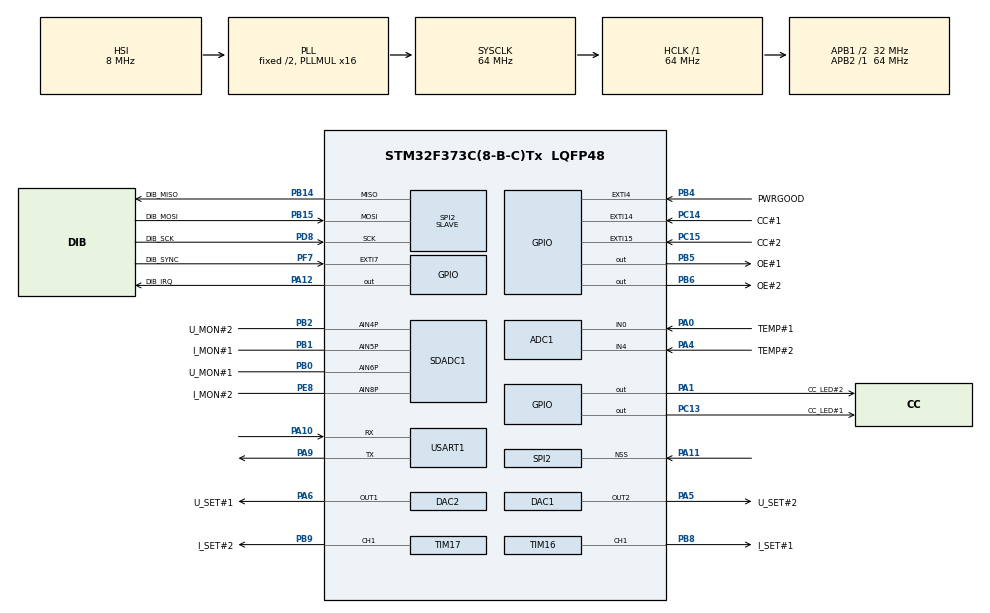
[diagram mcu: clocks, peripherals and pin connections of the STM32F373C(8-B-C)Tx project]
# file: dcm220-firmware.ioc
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ADC1.Channel-0\#ChannelRegularConversion=ADC_CHANNEL_0
ADC1.Channel-1\#ChannelRegularConversion=ADC_CHANNEL_4
ADC1.Channel-2\#ChannelRegularConversion=ADC_CHANNEL_TEMPSENSOR
ADC1.ContinuousConvMode=DISABLE
ADC1.DiscontinuousConvMode=DISABLE
ADC1.NbrOfConversion=3
ADC1.NbrOfConversionFlag=1
ADC1.Rank-0\#ChannelRegularConversion=1
ADC1.Rank-1\#ChannelRegularConversion=2
ADC1.Rank-2\#ChannelRegularConversion=3
ADC1.SamplingTime-0\#ChannelRegularConversion=ADC_SAMPLETIME_239CYCLES_5
ADC1.SamplingTime-1\#ChannelRegularConversion=ADC_SAMPLETIME_239CYCLES_5
ADC1.SamplingTime-2\#ChannelRegularConversion=ADC_SAMPLETIME_239CYCLES_5
ADC1.master=1
Dma.ADC1.0.Direction=DMA_PERIPH_TO_MEMORY
Dma.ADC1.0.Instance=DMA1_Channel1
Dma.ADC1.0.MemDataAlignment=DMA_MDATAALIGN_WORD
Dma.ADC1.0.MemInc=DMA_MINC_ENABLE
Dma.ADC1.0.Mode=DMA_NORMAL
Dma.ADC1.0.PeriphDataAlignment=DMA_PDATAALIGN_WORD
Dma.ADC1.0.PeriphInc=DMA_PINC_DISABLE
Dma.ADC1.0.Priority=DMA_PRIORITY_LOW
Dma.Request0=ADC1
Dma.Request1=SPI2_RX
Dma.Request2=SPI2_TX
Dma.SPI2_RX.1.Direction=DMA_PERIPH_TO_MEMORY
Dma.SPI2_RX.1.Instance=DMA1_Channel4
Dma.SPI2_RX.1.MemDataAlignment=DMA_MDATAALIGN_BYTE
Dma.SPI2_RX.1.MemInc=DMA_MINC_ENABLE
Dma.SPI2_RX.1.Mode=DMA_NORMAL
Dma.SPI2_RX.1.PeriphDataAlignment=DMA_PDATAALIGN_BYTE
Dma.SPI2_RX.1.PeriphInc=DMA_PINC_DISABLE
Dma.SPI2_RX.1.Priority=DMA_PRIORITY_LOW
Dma.SPI2_TX.2.Direction=DMA_MEMORY_TO_PERIPH
Dma.SPI2_TX.2.Instance=DMA1_Channel5
Dma.SPI2_TX.2.MemDataAlignment=DMA_MDATAALIGN_BYTE
Dma.SPI2_TX.2.MemInc=DMA_MINC_ENABLE
Dma.SPI2_TX.2.Mode=DMA_NORMAL
Dma.SPI2_TX.2.PeriphDataAlignment=DMA_PDATAALIGN_BYTE
Dma.SPI2_TX.2.PeriphInc=DMA_PINC_DISABLE
Dma.SPI2_TX.2.Priority=DMA_PRIORITY_LOW
Mcu.Family=STM32F3
Mcu.Name=STM32F373C(8-B-C)Tx
Mcu.Package=LQFP48
NVIC.ADC1_IRQn=true\:0\:0\:false\:false\:true\:true\:true
NVIC.DMA1_Channel1_IRQn=true\:0\:0\:false\:false\:true\:false\:true
NVIC.DMA1_Channel4_IRQn=true\:0\:0\:false\:false\:true\:false\:true
NVIC.DMA1_Channel5_IRQn=true\:0\:0\:false\:false\:true\:false\:true
NVIC.EXTI15_10_IRQn=true\:0\:0\:false\:false\:true\:true\:true
NVIC.EXTI4_IRQn=true\:0\:0\:false\:false\:true\:true\:true
NVIC.EXTI9_5_IRQn=true\:0\:0\:false\:false\:true\:true\:true
NVIC.PriorityGroup=NVIC_PRIORITYGROUP_4
PA0.GPIO_Label=TEMP\#1
PA0.Mode=IN0
PA0.Signal=ADC1_IN0
PA1.GPIO_Label=CC_LED\#2
PA1.Signal=GPIO_Output
PA10.Mode=Asynchronous
PA10.Signal=USART1_RX
PA11.Mode=NSS_Signal_Hard_Input
PA11.Signal=SPI2_NSS
PA12.GPIO_Label=DIB_IRQ
PA12.PinState=GPIO_PIN_SET
PA12.Signal=GPIO_Output
PA13.Mode=Trace_Asynchronous_SW
PA13.Signal=SYS_JTMS-SWDIO
PA14.Mode=Trace_Asynchronous_SW
PA14.Signal=SYS_JTCK-SWCLK
PA4.GPIO_Label=TEMP\#2
PA4.Mode=IN4
PA4.Signal=ADC1_IN4
PA5.GPIO_Label=U_SET\#2
PA5.Signal=COMP_DAC12_group
PA6.GPIO_Label=U_SET\#1
PA6.Signal=COMP_DAC21_group
PA9.Mode=Asynchronous
PA9.Signal=USART1_TX
PB0.GPIO_Label=U_MON\#1
PB0.Mode=IN6-Single-Ended zero reference
PB0.Signal=SDADC1_AIN6P
PB1.GPIO_Label=I_MON\#1
PB1.Mode=IN5-Single-Ended zero reference
PB1.Signal=SDADC1_AIN5P
PB14.GPIO_Label=DIB_MISO
PB14.Mode=Full_Duplex_Slave
PB14.Signal=SPI2_MISO
PB15.GPIO_Label=DIB_MOSI
PB15.Mode=Full_Duplex_Slave
PB15.Signal=SPI2_MOSI
PB2.GPIO_Label=U_MON\#2
PB2.Mode=IN4-Single-Ended zero reference
PB2.Signal=SDADC1_AIN4P
PB3.Mode=Trace_Asynchronous_SW
PB3.Signal=SYS_JTDO-TRACESWO
PB4.GPIO_Label=PWRGOOD
PB4.GPIO_ModeDefaultEXTI=GPIO_MODE_IT_RISING_FALLING
PB4.GPIO_PuPd=GPIO_PULLUP
PB4.Signal=GPXTI4
PB5.GPIO_Label=OE\#1
PB5.Signal=GPIO_Output
PB6.GPIO_Label=OE\#2
PB6.Signal=GPIO_Output
PB8.GPIO_Label=I_SET\#1
PB8.Signal=S_TIM16_CH1
PB9.GPIO_Label=I_SET\#2
PB9.Signal=S_TIM17_CH1
PC13.GPIO_Label=CC_LED\#1
PC13.Signal=GPIO_Output
PC14-OSC32_IN.GPIO_Label=CC\#1
PC14-OSC32_IN.GPIO_ModeDefaultEXTI=GPIO_MODE_IT_RISING_FALLING
PC14-OSC32_IN.Signal=GPXTI14
PC15-OSC32_OUT.GPIO_Label=CC\#2
PC15-OSC32_OUT.GPIO_ModeDefaultEXTI=GPIO_MODE_IT_RISING_FALLING
PC15-OSC32_OUT.Signal=GPXTI15
PD8.GPIO_Label=DIB_SCK
PD8.Mode=Full_Duplex_Slave
PD8.Signal=SPI2_SCK
PE8.GPIO_Label=I_MON\#2
PE8.Mode=IN8-Single-Ended zero reference
PE8.Signal=SDADC1_AIN8P
PF7.GPIO_Label=DIB_SYNC
PF7.Signal=GPXTI7
ProjectManager.HeapSize=0x200
ProjectManager.StackSize=0x400
ProjectManager.TargetToolchain=STM32CubeIDE
RCC.AHBFreq_Value=64000000
RCC.APB1CLKDivider=RCC_HCLK_DIV2
RCC.APB1Freq_Value=32000000
RCC.APB1TimFreq_Value=64000000
RCC.APB2Freq_Value=64000000
RCC.APB2TimFreq_Value=64000000
RCC.CortexFreq_Value=64000000
RCC.HCLKFreq_Value=64000000
RCC.HSE_VALUE=16000000
RCC.HSI_VALUE=8000000
RCC.LSE_VALUE=32768
RCC.PLLMUL=RCC_PLL_MUL16
RCC.RCC_PLLsource_Clock_Source_FROM_HSE=RCC_HSE_PREDIV_DIV2
RCC.SDADCPresc=RCC_SDADCSYSCLK_DIV16
RCC.SYSCLKFreq_VALUE=64000000
RCC.SYSCLKSource=RCC_SYSCLKSOURCE_PLLCLK
RCC.USBFreq_Value=64000000
SDADC1.Gain0=SDADC_GAIN_1
SDADC1.Gain1=SDADC_GAIN_2
SDADC1.InputMode0=SDADC_INPUT_MODE_SE_ZERO_REFERENCE
SDADC1.InputMode1=SDADC_INPUT_MODE_SE_ZERO_REFERENCE
SDADC1.NbrOfConversionFlag=1
SDADC1.ReferenceVoltage=SDADC_VREF_EXT
SH.COMP_DAC12_group.0=DAC1_OUT2,Enable_DAC_OUT2
SH.COMP_DAC21_group.0=DAC2_OUT1,DAC_OUT1
SH.S_TIM16_CH1.0=TIM16_CH1,PWM Generation1 CH1
SH.S_TIM17_CH1.0=TIM17_CH1,PWM Generation1 CH1
SPI2.DataSize=SPI_DATASIZE_8BIT
SPI2.Direction=SPI_DIRECTION_2LINES
SPI2.Mode=SPI_MODE_SLAVE
SPI2.VirtualNSS=VM_NSSHARD
SPI2.VirtualType=VM_SLAVE
TIM16.Channel=TIM_CHANNEL_1
TIM16.Period=1439
TIM16.Prescaler=0
TIM17.Channel=TIM_CHANNEL_1
TIM17.Period=1439
USART1.VirtualMode-Asynchronous=VM_ASYNC
VP_ADC1_TempSens_Input.Mode=IN-TempSens
VP_CRC_VS_CRC.Mode=CRC_Activate
VP_SDADC1_CONF0.Mode=ConfigZero
VP_SDADC1_CONF1.Mode=ConfigUn
VP_TIM16_VS_ClockSourceINT.Mode=Enable_Timer
VP_TIM17_VS_ClockSourceINT.Mode=Enable_Timer
board=custom

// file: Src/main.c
/* USER CODE BEGIN Header */
/**
  ******************************************************************************
  * @file           : main.c
  * @brief          : Main program body
  ******************************************************************************
  * @attention
  *
  * <h2><center>&copy; Copyright (c) 2019 STMicroelectronics.
  * All rights reserved.</center></h2>
  *
  * This software component is licensed by ST under BSD 3-Clause license,
  * the "License"; You may not use this file except in compliance with the
  * License. You may obtain a copy of the License at:
  *                        opensource.org/licenses/BSD-3-Clause
  *
  ******************************************************************************
  */
/* USER CODE END Header */

#include "main.h"

ADC_HandleTypeDef hadc1;
DMA_HandleTypeDef hdma_adc1;

CRC_HandleTypeDef hcrc;

DAC_HandleTypeDef hdac1;
DAC_HandleTypeDef hdac2;

SDADC_HandleTypeDef hsdadc1;

SPI_HandleTypeDef hspi2;
DMA_HandleTypeDef hdma_spi2_rx;
DMA_HandleTypeDef hdma_spi2_tx;

TIM_HandleTypeDef htim16;
TIM_HandleTypeDef htim17;

UART_HandleTypeDef huart1;

void SystemClock_Config(void);
static void MX_GPIO_Init(void);
static void MX_DMA_Init(void);
static void MX_ADC1_Init(void);
static void MX_SDADC1_Init(void);
static void MX_SPI2_Init(void);
static void MX_DAC1_Init(void);
static void MX_DAC2_Init(void);
static void MX_TIM16_Init(void);
static void MX_TIM17_Init(void);
static void MX_CRC_Init(void);
static void MX_USART1_UART_Init(void);

/* USER CODE BEGIN 0 */
void setup();
void loop();
/* USER CODE END 0 */

int main(void)
{

  /* MCU Configuration--------------------------------------------------------*/

  /* Reset of all peripherals, Initializes the Flash interface and the Systick. */
  HAL_Init();

  /* Configure the system clock */
  SystemClock_Config();

  /* Initialize all configured peripherals */
  MX_GPIO_Init();
  MX_DMA_Init();
  MX_ADC1_Init();
  MX_SDADC1_Init();
  MX_SPI2_Init();
  MX_DAC1_Init();
  MX_DAC2_Init();
  MX_TIM16_Init();
  MX_TIM17_Init();
  MX_CRC_Init();
  MX_USART1_UART_Init();
  /* USER CODE BEGIN 2 */

  setup();

  /* USER CODE END 2 */

  /* Infinite loop */
  while (1)
  {

    /* USER CODE BEGIN 3 */
	  loop();
  }
  /* USER CODE END 3 */
}

void SystemClock_Config(void)
{
  RCC_OscInitTypeDef RCC_OscInitStruct = {0};
  RCC_ClkInitTypeDef RCC_ClkInitStruct = {0};
  RCC_PeriphCLKInitTypeDef PeriphClkInit = {0};

  /** Initializes the CPU, AHB and APB busses clocks
  */
  RCC_OscInitStruct.OscillatorType = RCC_OSCILLATORTYPE_HSI;
  RCC_OscInitStruct.HSIState = RCC_HSI_ON;
  RCC_OscInitStruct.HSICalibrationValue = RCC_HSICALIBRATION_DEFAULT;
  RCC_OscInitStruct.PLL.PLLState = RCC_PLL_ON;
  RCC_OscInitStruct.PLL.PLLSource = RCC_PLLSOURCE_HSI;
  RCC_OscInitStruct.PLL.PLLMUL = RCC_PLL_MUL16;
  if (HAL_RCC_OscConfig(&RCC_OscInitStruct) != HAL_OK)
  {
    Error_Handler();
  }
  /** Initializes the CPU, AHB and APB busses clocks
  */
  RCC_ClkInitStruct.ClockType = RCC_CLOCKTYPE_HCLK|RCC_CLOCKTYPE_SYSCLK
                              |RCC_CLOCKTYPE_PCLK1|RCC_CLOCKTYPE_PCLK2;
  RCC_ClkInitStruct.SYSCLKSource = RCC_SYSCLKSOURCE_PLLCLK;
  RCC_ClkInitStruct.AHBCLKDivider = RCC_SYSCLK_DIV1;
  RCC_ClkInitStruct.APB1CLKDivider = RCC_HCLK_DIV2;
  RCC_ClkInitStruct.APB2CLKDivider = RCC_HCLK_DIV1;

  if (HAL_RCC_ClockConfig(&RCC_ClkInitStruct, FLASH_LATENCY_2) != HAL_OK)
  {
    Error_Handler();
  }
  PeriphClkInit.PeriphClockSelection = RCC_PERIPHCLK_USART1|RCC_PERIPHCLK_ADC1
                              |RCC_PERIPHCLK_SDADC;
  PeriphClkInit.Usart1ClockSelection = RCC_USART1CLKSOURCE_PCLK2;
  PeriphClkInit.SdadcClockSelection = RCC_SDADCSYSCLK_DIV16;
  PeriphClkInit.Adc1ClockSelection = RCC_ADC1PCLK2_DIV2;

  if (HAL_RCCEx_PeriphCLKConfig(&PeriphClkInit) != HAL_OK)
  {
    Error_Handler();
  }
  HAL_PWREx_EnableSDADC(PWR_SDADC_ANALOG1);
}

static void MX_ADC1_Init(void)
{

  ADC_ChannelConfTypeDef sConfig = {0};

  /** Common config
  */
  hadc1.Instance = ADC1;
  hadc1.Init.ScanConvMode = ADC_SCAN_ENABLE;
  hadc1.Init.ContinuousConvMode = DISABLE;
  hadc1.Init.DiscontinuousConvMode = DISABLE;
  hadc1.Init.ExternalTrigConv = ADC_SOFTWARE_START;
  hadc1.Init.DataAlign = ADC_DATAALIGN_RIGHT;
  hadc1.Init.NbrOfConversion = 3;
  if (HAL_ADC_Init(&hadc1) != HAL_OK)
  {
    Error_Handler();
  }
  /** Configure Regular Channel
  */
  sConfig.Channel = ADC_CHANNEL_0;
  sConfig.Rank = ADC_REGULAR_RANK_1;
  sConfig.SamplingTime = ADC_SAMPLETIME_239CYCLES_5;
  if (HAL_ADC_ConfigChannel(&hadc1, &sConfig) != HAL_OK)
  {
    Error_Handler();
  }
  /** Configure Regular Channel
  */
  sConfig.Channel = ADC_CHANNEL_4;
  sConfig.Rank = ADC_REGULAR_RANK_2;
  if (HAL_ADC_ConfigChannel(&hadc1, &sConfig) != HAL_OK)
  {
    Error_Handler();
  }
  /** Configure Regular Channel
  */
  sConfig.Channel = ADC_CHANNEL_TEMPSENSOR;
  sConfig.Rank = ADC_REGULAR_RANK_3;
  if (HAL_ADC_ConfigChannel(&hadc1, &sConfig) != HAL_OK)
  {
    Error_Handler();
  }

}

static void MX_CRC_Init(void)
{

  hcrc.Instance = CRC;
  hcrc.Init.DefaultPolynomialUse = DEFAULT_POLYNOMIAL_ENABLE;
  hcrc.Init.DefaultInitValueUse = DEFAULT_INIT_VALUE_ENABLE;
  hcrc.Init.InputDataInversionMode = CRC_INPUTDATA_INVERSION_NONE;
  hcrc.Init.OutputDataInversionMode = CRC_OUTPUTDATA_INVERSION_DISABLE;
  hcrc.InputDataFormat = CRC_INPUTDATA_FORMAT_BYTES;
  if (HAL_CRC_Init(&hcrc) != HAL_OK)
  {
    Error_Handler();
  }

}

static void MX_DAC1_Init(void)
{

  DAC_ChannelConfTypeDef sConfig = {0};

  /** DAC Initialization
  */
  hdac1.Instance = DAC1;
  if (HAL_DAC_Init(&hdac1) != HAL_OK)
  {
    Error_Handler();
  }
  /** DAC channel OUT2 config
  */
  sConfig.DAC_Trigger = DAC_TRIGGER_NONE;
  sConfig.DAC_OutputBuffer = DAC_OUTPUTBUFFER_ENABLE;
  if (HAL_DAC_ConfigChannel(&hdac1, &sConfig, DAC_CHANNEL_2) != HAL_OK)
  {
    Error_Handler();
  }

}

static void MX_DAC2_Init(void)
{

  DAC_ChannelConfTypeDef sConfig = {0};

  /** DAC Initialization
  */
  hdac2.Instance = DAC2;
  if (HAL_DAC_Init(&hdac2) != HAL_OK)
  {
    Error_Handler();
  }
  /** DAC channel OUT1 config
  */
  sConfig.DAC_Trigger = DAC_TRIGGER_NONE;
  sConfig.DAC_OutputBuffer = DAC_OUTPUTBUFFER_ENABLE;
  if (HAL_DAC_ConfigChannel(&hdac2, &sConfig, DAC_CHANNEL_1) != HAL_OK)
  {
    Error_Handler();
  }

}

static void MX_SDADC1_Init(void)
{

  SDADC_ConfParamTypeDef ConfParamStruct = {0};

  /** Configure the SDADC low power mode, fast conversion mode,
  slow clock mode and SDADC1 reference voltage
  */
  hsdadc1.Instance = SDADC1;
  hsdadc1.Init.IdleLowPowerMode = SDADC_LOWPOWER_NONE;
  hsdadc1.Init.FastConversionMode = SDADC_FAST_CONV_DISABLE;
  hsdadc1.Init.SlowClockMode = SDADC_SLOW_CLOCK_DISABLE;
  hsdadc1.Init.ReferenceVoltage = SDADC_VREF_EXT;
  if (HAL_SDADC_Init(&hsdadc1) != HAL_OK)
  {
    Error_Handler();
  }
  /** Set parameters for SDADC configuration 0 Register
  */
  ConfParamStruct.InputMode = SDADC_INPUT_MODE_SE_ZERO_REFERENCE;
  ConfParamStruct.Gain = SDADC_GAIN_1;
  ConfParamStruct.CommonMode = SDADC_COMMON_MODE_VSSA;
  ConfParamStruct.Offset = 0;
  if (HAL_SDADC_PrepareChannelConfig(&hsdadc1, SDADC_CONF_INDEX_0, &ConfParamStruct) != HAL_OK)
  {
    Error_Handler();
  }
  /** Set parameters for SDADC configuration 1 Register
  */
  ConfParamStruct.Gain = SDADC_GAIN_2;
  if (HAL_SDADC_PrepareChannelConfig(&hsdadc1, SDADC_CONF_INDEX_1, &ConfParamStruct) != HAL_OK)
  {
    Error_Handler();
  }

}

static void MX_SPI2_Init(void)
{

  /* SPI2 parameter configuration*/
  hspi2.Instance = SPI2;
  hspi2.Init.Mode = SPI_MODE_SLAVE;
  hspi2.Init.Direction = SPI_DIRECTION_2LINES;
  hspi2.Init.DataSize = SPI_DATASIZE_8BIT;
  hspi2.Init.CLKPolarity = SPI_POLARITY_LOW;
  hspi2.Init.CLKPhase = SPI_PHASE_1EDGE;
  hspi2.Init.NSS = SPI_NSS_HARD_INPUT;
  hspi2.Init.FirstBit = SPI_FIRSTBIT_MSB;
  hspi2.Init.TIMode = SPI_TIMODE_DISABLE;
  hspi2.Init.CRCCalculation = SPI_CRCCALCULATION_DISABLE;
  hspi2.Init.CRCPolynomial = 7;
  hspi2.Init.CRCLength = SPI_CRC_LENGTH_DATASIZE;
  hspi2.Init.NSSPMode = SPI_NSS_PULSE_DISABLE;
  if (HAL_SPI_Init(&hspi2) != HAL_OK)
  {
    Error_Handler();
  }

}

static void MX_TIM16_Init(void)
{

  TIM_OC_InitTypeDef sConfigOC = {0};
  TIM_BreakDeadTimeConfigTypeDef sBreakDeadTimeConfig = {0};

  htim16.Instance = TIM16;
  htim16.Init.Prescaler = 0;
  htim16.Init.CounterMode = TIM_COUNTERMODE_UP;
  htim16.Init.Period = 1439;
  htim16.Init.ClockDivision = TIM_CLOCKDIVISION_DIV1;
  htim16.Init.RepetitionCounter = 0;
  htim16.Init.AutoReloadPreload = TIM_AUTORELOAD_PRELOAD_DISABLE;
  if (HAL_TIM_Base_Init(&htim16) != HAL_OK)
  {
    Error_Handler();
  }
  if (HAL_TIM_PWM_Init(&htim16) != HAL_OK)
  {
    Error_Handler();
  }
  sConfigOC.OCMode = TIM_OCMODE_PWM1;
  sConfigOC.Pulse = 0;
  sConfigOC.OCPolarity = TIM_OCPOLARITY_HIGH;
  sConfigOC.OCNPolarity = TIM_OCNPOLARITY_HIGH;
  sConfigOC.OCFastMode = TIM_OCFAST_DISABLE;
  sConfigOC.OCIdleState = TIM_OCIDLESTATE_RESET;
  sConfigOC.OCNIdleState = TIM_OCNIDLESTATE_RESET;
  if (HAL_TIM_PWM_ConfigChannel(&htim16, &sConfigOC, TIM_CHANNEL_1) != HAL_OK)
  {
    Error_Handler();
  }
  sBreakDeadTimeConfig.OffStateRunMode = TIM_OSSR_DISABLE;
  sBreakDeadTimeConfig.OffStateIDLEMode = TIM_OSSI_DISABLE;
  sBreakDeadTimeConfig.LockLevel = TIM_LOCKLEVEL_OFF;
  sBreakDeadTimeConfig.DeadTime = 0;
  sBreakDeadTimeConfig.BreakState = TIM_BREAK_DISABLE;
  sBreakDeadTimeConfig.BreakPolarity = TIM_BREAKPOLARITY_HIGH;
  sBreakDeadTimeConfig.AutomaticOutput = TIM_AUTOMATICOUTPUT_DISABLE;
  if (HAL_TIMEx_ConfigBreakDeadTime(&htim16, &sBreakDeadTimeConfig) != HAL_OK)
  {
    Error_Handler();
  }
  HAL_TIM_MspPostInit(&htim16);

}

static void MX_TIM17_Init(void)
{

  TIM_OC_InitTypeDef sConfigOC = {0};
  TIM_BreakDeadTimeConfigTypeDef sBreakDeadTimeConfig = {0};

  htim17.Instance = TIM17;
  htim17.Init.Prescaler = 0;
  htim17.Init.CounterMode = TIM_COUNTERMODE_UP;
  htim17.Init.Period = 1439;
  htim17.Init.ClockDivision = TIM_CLOCKDIVISION_DIV1;
  htim17.Init.RepetitionCounter = 0;
  htim17.Init.AutoReloadPreload = TIM_AUTORELOAD_PRELOAD_DISABLE;
  if (HAL_TIM_Base_Init(&htim17) != HAL_OK)
  {
    Error_Handler();
  }
  if (HAL_TIM_PWM_Init(&htim17) != HAL_OK)
  {
    Error_Handler();
  }
  sConfigOC.OCMode = TIM_OCMODE_PWM1;
  sConfigOC.Pulse = 0;
  sConfigOC.OCPolarity = TIM_OCPOLARITY_HIGH;
  sConfigOC.OCNPolarity = TIM_OCNPOLARITY_HIGH;
  sConfigOC.OCFastMode = TIM_OCFAST_DISABLE;
  sConfigOC.OCIdleState = TIM_OCIDLESTATE_RESET;
  sConfigOC.OCNIdleState = TIM_OCNIDLESTATE_RESET;
  if (HAL_TIM_PWM_ConfigChannel(&htim17, &sConfigOC, TIM_CHANNEL_1) != HAL_OK)
  {
    Error_Handler();
  }
  sBreakDeadTimeConfig.OffStateRunMode = TIM_OSSR_DISABLE;
  sBreakDeadTimeConfig.OffStateIDLEMode = TIM_OSSI_DISABLE;
  sBreakDeadTimeConfig.LockLevel = TIM_LOCKLEVEL_OFF;
  sBreakDeadTimeConfig.DeadTime = 0;
  sBreakDeadTimeConfig.BreakState = TIM_BREAK_DISABLE;
  sBreakDeadTimeConfig.BreakPolarity = TIM_BREAKPOLARITY_HIGH;
  sBreakDeadTimeConfig.AutomaticOutput = TIM_AUTOMATICOUTPUT_DISABLE;
  if (HAL_TIMEx_ConfigBreakDeadTime(&htim17, &sBreakDeadTimeConfig) != HAL_OK)
  {
    Error_Handler();
  }
  HAL_TIM_MspPostInit(&htim17);

}

static void MX_USART1_UART_Init(void)
{

  huart1.Instance = USART1;
  huart1.Init.BaudRate = 38400;
  huart1.Init.WordLength = UART_WORDLENGTH_8B;
  huart1.Init.StopBits = UART_STOPBITS_1;
  huart1.Init.Parity = UART_PARITY_NONE;
  huart1.Init.Mode = UART_MODE_TX_RX;
  huart1.Init.HwFlowCtl = UART_HWCONTROL_NONE;
  huart1.Init.OverSampling = UART_OVERSAMPLING_16;
  huart1.Init.OneBitSampling = UART_ONE_BIT_SAMPLE_DISABLE;
  huart1.AdvancedInit.AdvFeatureInit = UART_ADVFEATURE_NO_INIT;
  if (HAL_UART_Init(&huart1) != HAL_OK)
  {
    Error_Handler();
  }

}

static void MX_DMA_Init(void)
{

  /* DMA controller clock enable */
  __HAL_RCC_DMA1_CLK_ENABLE();

  /* DMA interrupt init */
  /* DMA1_Channel1_IRQn interrupt configuration */
  HAL_NVIC_SetPriority(DMA1_Channel1_IRQn, 0, 0);
  HAL_NVIC_EnableIRQ(DMA1_Channel1_IRQn);
  /* DMA1_Channel4_IRQn interrupt configuration */
  HAL_NVIC_SetPriority(DMA1_Channel4_IRQn, 0, 0);
  HAL_NVIC_EnableIRQ(DMA1_Channel4_IRQn);
  /* DMA1_Channel5_IRQn interrupt configuration */
  HAL_NVIC_SetPriority(DMA1_Channel5_IRQn, 0, 0);
  HAL_NVIC_EnableIRQ(DMA1_Channel5_IRQn);

}

static void MX_GPIO_Init(void)
{
  GPIO_InitTypeDef GPIO_InitStruct = {0};

  /* GPIO Ports Clock Enable */
  __HAL_RCC_GPIOC_CLK_ENABLE();
  __HAL_RCC_GPIOA_CLK_ENABLE();
  __HAL_RCC_GPIOB_CLK_ENABLE();
  __HAL_RCC_GPIOE_CLK_ENABLE();
  __HAL_RCC_GPIOD_CLK_ENABLE();
  __HAL_RCC_GPIOF_CLK_ENABLE();

  /*Configure GPIO pin Output Level */
  HAL_GPIO_WritePin(CC_LED_1_GPIO_Port, CC_LED_1_Pin, GPIO_PIN_RESET);

  /*Configure GPIO pin Output Level */
  HAL_GPIO_WritePin(CC_LED_2_GPIO_Port, CC_LED_2_Pin, GPIO_PIN_RESET);

  /*Configure GPIO pin Output Level */
  HAL_GPIO_WritePin(DIB_IRQ_GPIO_Port, DIB_IRQ_Pin, GPIO_PIN_SET);

  /*Configure GPIO pin Output Level */
  HAL_GPIO_WritePin(GPIOB, OE_1_Pin|OE_2_Pin, GPIO_PIN_RESET);

  /*Configure GPIO pin : CC_LED_1_Pin */
  GPIO_InitStruct.Pin = CC_LED_1_Pin;
  GPIO_InitStruct.Mode = GPIO_MODE_OUTPUT_PP;
  GPIO_InitStruct.Pull = GPIO_NOPULL;
  GPIO_InitStruct.Speed = GPIO_SPEED_FREQ_LOW;
  HAL_GPIO_Init(CC_LED_1_GPIO_Port, &GPIO_InitStruct);

  /*Configure GPIO pins : CC_1_Pin CC_2_Pin */
  GPIO_InitStruct.Pin = CC_1_Pin|CC_2_Pin;
  GPIO_InitStruct.Mode = GPIO_MODE_IT_RISING_FALLING;
  GPIO_InitStruct.Pull = GPIO_NOPULL;
  HAL_GPIO_Init(GPIOC, &GPIO_InitStruct);

  /*Configure GPIO pins : CC_LED_2_Pin DIB_IRQ_Pin */
  GPIO_InitStruct.Pin = CC_LED_2_Pin|DIB_IRQ_Pin;
  GPIO_InitStruct.Mode = GPIO_MODE_OUTPUT_PP;
  GPIO_InitStruct.Pull = GPIO_NOPULL;
  GPIO_InitStruct.Speed = GPIO_SPEED_FREQ_LOW;
  HAL_GPIO_Init(GPIOA, &GPIO_InitStruct);

  /*Configure GPIO pin : DIB_SYNC_Pin */
  GPIO_InitStruct.Pin = DIB_SYNC_Pin;
  GPIO_InitStruct.Mode = GPIO_MODE_IT_RISING;
  GPIO_InitStruct.Pull = GPIO_NOPULL;
  HAL_GPIO_Init(DIB_SYNC_GPIO_Port, &GPIO_InitStruct);

  /*Configure GPIO pin : PWRGOOD_Pin */
  GPIO_InitStruct.Pin = PWRGOOD_Pin;
  GPIO_InitStruct.Mode = GPIO_MODE_IT_RISING_FALLING;
  GPIO_InitStruct.Pull = GPIO_PULLUP;
  HAL_GPIO_Init(PWRGOOD_GPIO_Port, &GPIO_InitStruct);

  /*Configure GPIO pins : OE_1_Pin OE_2_Pin */
  GPIO_InitStruct.Pin = OE_1_Pin|OE_2_Pin;
  GPIO_InitStruct.Mode = GPIO_MODE_OUTPUT_PP;
  GPIO_InitStruct.Pull = GPIO_NOPULL;
  GPIO_InitStruct.Speed = GPIO_SPEED_FREQ_LOW;
  HAL_GPIO_Init(GPIOB, &GPIO_InitStruct);

  /* EXTI interrupt init*/
  HAL_NVIC_SetPriority(EXTI4_IRQn, 0, 0);
  HAL_NVIC_EnableIRQ(EXTI4_IRQn);

  HAL_NVIC_SetPriority(EXTI9_5_IRQn, 0, 0);
  HAL_NVIC_EnableIRQ(EXTI9_5_IRQn);

  HAL_NVIC_SetPriority(EXTI15_10_IRQn, 0, 0);
  HAL_NVIC_EnableIRQ(EXTI15_10_IRQn);

}

void Error_Handler(void)
{
}

/************************ (C) COPYRIGHT STMicroelectronics *****END OF FILE****/
